# MK22F10 register map
File version: 1.6
Registers are 32-bit, read-write, reset 0x0 unless marked. A register's access mark holds for its fields unless they carry their own. Offsets are from the block's base; [hi:lo] are bit positions; {n}, {i} and the like mark numbered series; 'fields as' and 'values as' point back to an identical list.

## SIM — System Integration Module
Base 0x40047000; register names take the prefix SIM_
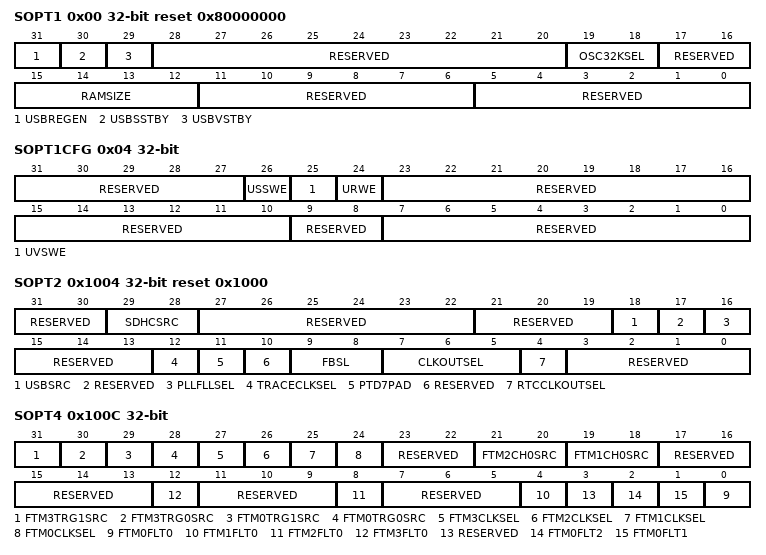
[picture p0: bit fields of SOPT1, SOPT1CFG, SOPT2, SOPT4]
0x00 SOPT1 reset 0x80000000 (reset mask 0xFFFF0FC0) — System Options Register 1
  [31] USBREGEN — USB voltage regulator enable
    0=USB voltage regulator is disabled; 1=USB voltage regulator is enabled
  [30] USBSSTBY — USB voltage regulator in standby mode during Stop, VLPS, LLS and VLLS modes.
    0=USB voltage regulator not in standby during Stop, VLPS, LLS and VLLS modes; 1=USB voltage regulator in standby during Stop, VLPS, LLS and VLLS modes
  [29] USBVSTBY — USB voltage regulator in standby mode during VLPR and VLPW modes
    0=USB voltage regulator not in standby during VLPR and VLPW modes; 1=USB voltage regulator in standby during VLPR and VLPW modes
  [28:20] RESERVED ro
  [19:18] OSC32KSEL — 32K oscillator clock select
    0=System oscillator (OSC32KCLK); 2=RTC 32.768kHz oscillator; 3=LPO 1 kHz
  [17:16] RESERVED ro
  [15:12] RAMSIZE ro
    0=Undefined; 2=Undefined; {v}=Undefined (v=4..8); 9=128 KBytes; {v}=Undefined (v=10..15)
  [11:6] RESERVED ro
  [5:0] RESERVED ro
0x04 SOPT1CFG — SOPT1 Configuration Register
  [31:27] RESERVED ro
  [26] USSWE — USB voltage regulator stop standby write enable
    0=SOPT1 USBSSTBY cannot be written; 1=SOPT1 USBSSTBY can be written
  [25] UVSWE — USB voltage regulator VLP standby write enable
    0=SOPT1 USBVSTBY cannot be written; 1=SOPT1 USBVSTBY can be written
  [24] URWE — USB voltage regulator enable write enable
    0=SOPT1 USBREGEN cannot be written; 1=SOPT1 USBREGEN can be written
  [23:10] RESERVED ro
  [9:8] RESERVED ro
  [7:0] RESERVED ro
0x1004 SOPT2 reset 0x1000 — System Options Register 2
  [31:30] RESERVED ro
  [29:28] SDHCSRC — SDHC clock source select
    0=Core/system clock; 1=MCGPLLCLK/MCGFLLCLK clock; 2=OSCERCLK clock; 3=External bypass clock (SDHC0_CLKIN)
  [27:22] RESERVED ro
  [21:19] RESERVED ro
  [18] USBSRC — USB clock source select
    0=External bypass clock (USB_CLKIN); 1=MCGPLLCLK/MCGFLLCLK clock divided by the USB fractional divider. See the SIM_CLKDIV2[USBFRAC, USBDIV] descriptions.
  [17] RESERVED ro
  [16] PLLFLLSEL — PLL/FLL clock select
    0=MCGFLLCLK clock; 1=MCGPLLCLK clock
  [15:13] RESERVED ro
  [12] TRACECLKSEL — Debug trace clock select
    0=MCGOUTCLK; 1=Core/system clock
  [11] PTD7PAD — PTD7 pad drive strength
    0=Single-pad drive strength for PTD7; 1=Double pad drive strength for PTD7
  [10] RESERVED ro
  [9:8] FBSL — FlexBus security level
    0=All off-chip accesses (instruction and data) via the FlexBus are disallowed; 1=All off-chip accesses (instruction and data) via the FlexBus are disallowed; 2=Off-chip instruction accesses are disallowed. Data accesses are allowed.; 3=Off-chip instruction accesses and data accesses are allowed
  [7:5] CLKOUTSEL — CLKOUT select
    0=FlexBus CLKOUT; 2=Flash clock; 3=LPO clock (1 kHz); 4=MCGIRCLK; 5=RTC 32.768kHz clock; 6=OSCERCLK0
  [4] RTCCLKOUTSEL — RTC clock out select
    0=RTC 1 Hz clock is output on the RTC_CLKOUT pin; 1=RTC 32.768kHz clock is output on the RTC_CLKOUT pin
  [3:0] RESERVED ro
0x100C SOPT4 — System Options Register 4
  [31] FTM3TRG1SRC — FlexTimer 3 Hardware Trigger 1 Source Select
    1=FTM2 channel match drives FTM3 hardware trigger 1
  [30] FTM3TRG0SRC — FlexTimer 3 Hardware Trigger 0 Source Select
    1=FTM1 channel match drives FTM3 hardware trigger 0
  [29] FTM0TRG1SRC — FlexTimer 0 Hardware Trigger 1 Source Select
    0=PDB output trigger 1 drives FTM0 hardware trigger 1; 1=FTM2 channel match drives FTM0 hardware trigger 1
  [28] FTM0TRG0SRC — FlexTimer 0 Hardware Trigger 0 Source Select
    0=HSCMP0 output drives FTM0 hardware trigger 0; 1=FTM1 channel match drives FTM0 hardware trigger 0
  [27] FTM3CLKSEL — FlexTimer 3 External Clock Pin Select
    0=FTM3 external clock driven by FTM_CLK0 pin; 1=FTM3 external clock driven by FTM_CLK1 pin
  [26] FTM2CLKSEL — FlexTimer 2 External Clock Pin Select
    0=FTM2 external clock driven by FTM_CLK0 pin; 1=FTM2 external clock driven by FTM_CLK1 pin
  [25] FTM1CLKSEL — FTM1 External Clock Pin Select
    0=FTM_CLK0 pin; 1=FTM_CLK1 pin
  [24] FTM0CLKSEL — FlexTimer 0 External Clock Pin Select
    0=FTM_CLK0 pin; 1=FTM_CLK1 pin
  [23:22] RESERVED ro
  [21:20] FTM2CH0SRC — FTM2 channel 0 input capture source select
    0=FTM2_CH0 signal; 1=CMP0 output; 2=CMP1 output
  [19:18] FTM1CH0SRC — FTM1 channel 0 input capture source select
    0=FTM1_CH0 signal; 1=CMP0 output; 2=CMP1 output; 3=USB start of frame pulse
  [17:13] RESERVED ro
  [4n] FTM{n}FLT0 (n=0..3) — FTM{n} Fault 0 Select
    0=FTM{n}_FLT0 pin; 1=CMP0 out
  [11:9] RESERVED ro
  [7:5] RESERVED ro
  [3] RESERVED ro
  [2] FTM0FLT2 — FTM0 Fault 2 Select
    0=FTM0_FLT2 pin; 1=CMP2 out
  [1] FTM0FLT1 — FTM0 Fault 1 Select
    0=FTM0_FLT1 pin; 1=CMP1 out
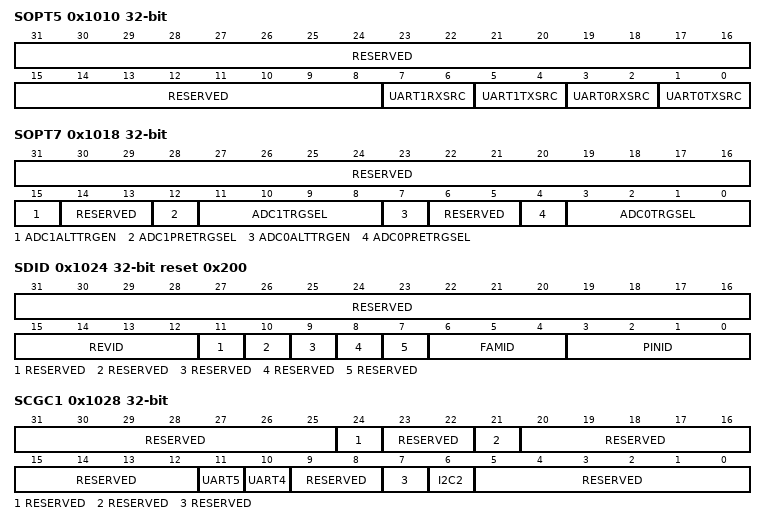
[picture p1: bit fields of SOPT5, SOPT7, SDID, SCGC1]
0x1010 SOPT5 — System Options Register 5
  [31:8] RESERVED ro
  [7:6] UART1RXSRC — UART 1 receive data source select
    0=UART1_RX pin; 1=CMP0; 2=CMP1
  [5:4] UART1TXSRC — UART 1 transmit data source select
    0=UART1_TX pin; 1=UART1_TX pin modulated with FTM1 channel 0 output; 2=UART1_TX pin modulated with FTM2 channel 0 output
  [3:2] UART0RXSRC — UART 0 receive data source select
    0=UART0_RX pin; 1=CMP0; 2=CMP1
  [1:0] UART0TXSRC — UART 0 transmit data source select
    0=UART0_TX pin; 1=UART0_TX pin modulated with FTM1 channel 0 output; 2=UART0_TX pin modulated with FTM2 channel 0 output
0x1018 SOPT7 — System Options Register 7
  [31:16] RESERVED ro
  [15] ADC1ALTTRGEN — ADC1 alternate trigger enable
    0=PDB trigger selected for ADC1; 1=Alternate trigger selected for ADC1 as defined by ADC1TRGSEL
  [14:13] RESERVED ro
  [12] ADC1PRETRGSEL — ADC1 pre-trigger select
    0=Pre-trigger A selected for ADC1; 1=Pre-trigger B selected for ADC1
  [11:8] ADC1TRGSEL — ADC1 trigger select
    0=PDB external trigger pin input (PDB0_EXTRG); 1=High speed comparator 0 output; 2=High speed comparator 1 output; 3=High speed comparator 2 output; {v}=PIT trigger {v-4} (v=4..7); 8=FTM0 trigger; 9=FTM1 trigger; 10=FTM2 trigger; 12=RTC alarm; 13=RTC seconds; 14=Low-power timer trigger
  [7] ADC0ALTTRGEN — ADC0 alternate trigger enable
    0=PDB trigger selected for ADC0; 1=Alternate trigger selected for ADC0
  [6:5] RESERVED ro
  [4] ADC0PRETRGSEL — ADC0 pretrigger select
    0=Pre-trigger A; 1=Pre-trigger B
  [3:0] ADC0TRGSEL — ADC0 trigger select
    values as ADC1TRGSEL
0x1024 SDID ro reset 0x200 (reset mask 0xF380) — System Device Identification Register
  [31:16] RESERVED
  [15:12] REVID — Device revision number
  [11] RESERVED
  [10] RESERVED
  [9] RESERVED
  [8] RESERVED
  [7] RESERVED
  [6:4] FAMID — Kinetis family identification
    1=K22
  [3:0] PINID — Pincount identification
    5=64-pin; 6=80-pin; 7=121-pin; 8=100-pin; 9=121-pin; 10=144-pin
0x1028 SCGC1 — System Clock Gating Control Register 1
  [31:25] RESERVED ro
  [24] RESERVED ro
  [23:22] RESERVED ro
  [21] RESERVED ro
  [20:12] RESERVED ro
  [11] UART5 — UART5 Clock Gate Control
    0=Clock disabled; 1=Clock enabled
  [10] UART4 — UART4 Clock Gate Control
    0=Clock disabled; 1=Clock enabled
  [9:8] RESERVED ro
  [7] RESERVED ro
  [6] I2C2 — I2C2 Clock Gate Control
    0=Clock disabled; 1=Clock enabled
  [5:0] RESERVED ro
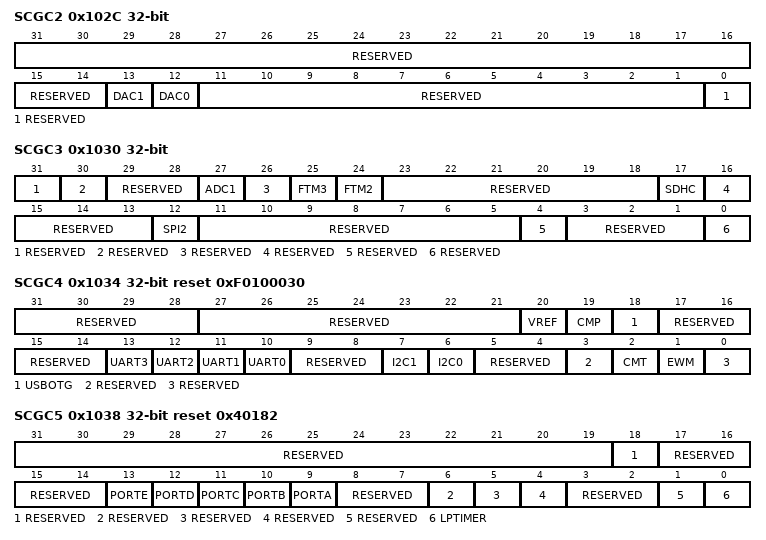
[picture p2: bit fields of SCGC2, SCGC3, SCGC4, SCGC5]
0x102C SCGC2 — System Clock Gating Control Register 2
  [31:14] RESERVED ro
  [13] DAC1 — DAC1 Clock Gate Control
    0=Clock disabled; 1=Clock enabled
  [12] DAC0 — DAC0 Clock Gate Control
    0=Clock disabled; 1=Clock enabled
  [11:1] RESERVED ro
  [0] RESERVED ro
0x1030 SCGC3 — System Clock Gating Control Register 3
  [31] RESERVED ro
  [30] RESERVED ro
  [29:28] RESERVED ro
  [27] ADC1 — ADC1 Clock Gate Control
    0=Clock disabled; 1=Clock enabled
  [26] RESERVED ro
  [25] FTM3 — FTM3 Clock Gate Control
    0=Clock disabled; 1=Clock enabled
  [24] FTM2 — FTM2 Clock Gate Control
    0=Clock disabled; 1=Clock enabled
  [23:18] RESERVED ro
  [17] SDHC — SDHC Clock Gate Control
    0=Clock disabled; 1=Clock enabled
  [16:13] RESERVED ro
  [12] SPI2 — SPI2 Clock Gate Control
    0=Clock disabled; 1=Clock enabled
  [11:5] RESERVED ro
  [4] RESERVED ro
  [3:1] RESERVED ro
  [0] RESERVED ro
0x1034 SCGC4 reset 0xF0100030 — System Clock Gating Control Register 4
  [31:28] RESERVED ro
  [27:21] RESERVED ro
  [20] VREF — VREF Clock Gate Control
    0=Clock disabled; 1=Clock enabled
  [19] CMP — Comparator Clock Gate Control
    0=Clock disabled; 1=Clock enabled
  [18] USBOTG — USB Clock Gate Control
    0=Clock disabled; 1=Clock enabled
  [17:14] RESERVED ro
  [n+10] UART{n} (n=0..3) — UART{n} Clock Gate Control
    0=Clock disabled; 1=Clock enabled
  [9:8] RESERVED ro
  [7] I2C1 — I2C1 Clock Gate Control
    0=Clock disabled; 1=Clock enabled
  [6] I2C0 — I2C0 Clock Gate Control
    0=Clock disabled; 1=Clock enabled
  [5:4] RESERVED ro
  [3] RESERVED ro
  [2] CMT — CMT Clock Gate Control
    0=Clock disabled; 1=Clock enabled
  [1] EWM — EWM Clock Gate Control
    0=Clock disabled; 1=Clock enabled
  [0] RESERVED ro
0x1038 SCGC5 reset 0x40182 — System Clock Gating Control Register 5
  [31:19] RESERVED ro
  [18] RESERVED ro
  [17:14] RESERVED ro
  [13] PORTE — Port E Clock Gate Control
    0=Clock disabled; 1=Clock enabled
  [12] PORTD — Port D Clock Gate Control
    0=Clock disabled; 1=Clock enabled
  [11] PORTC — Port C Clock Gate Control
    0=Clock disabled; 1=Clock enabled
  [10] PORTB — Port B Clock Gate Control
    0=Clock disabled; 1=Clock enabled
  [9] PORTA — Port A Clock Gate Control
    0=Clock disabled; 1=Clock enabled
  [8:7] RESERVED ro
  [6] RESERVED ro
  [5] RESERVED ro
  [4] RESERVED ro
  [3:2] RESERVED ro
  [1] RESERVED ro
  [0] LPTIMER — Low Power Timer Access Control
    0=Access disabled; 1=Access enabled
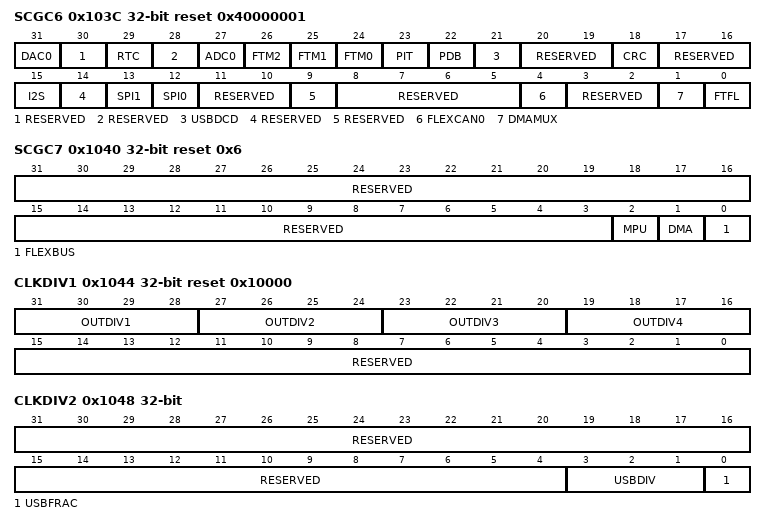
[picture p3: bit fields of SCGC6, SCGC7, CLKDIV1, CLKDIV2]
0x103C SCGC6 reset 0x40000001 — System Clock Gating Control Register 6
  [31] DAC0 — DAC0 Clock Gate Control
    0=Clock disabled; 1=Clock enabled
  [30] RESERVED ro
  [29] RTC — RTC Access Control
    0=Access and interrupts disabled; 1=Access and interrupts enabled
  [28] RESERVED ro
  [27] ADC0 — ADC0 Clock Gate Control
    0=Clock disabled; 1=Clock enabled
  [26] FTM2 — FTM2 Clock Gate Control
    0=Clock disabled; 1=Clock enabled
  [25] FTM1 — FTM1 Clock Gate Control
    0=Clock disabled; 1=Clock enabled
  [24] FTM0 — FTM0 Clock Gate Control
    0=Clock disabled; 1=Clock enabled
  [23] PIT — PIT Clock Gate Control
    0=Clock disabled; 1=Clock enabled
  [22] PDB — PDB Clock Gate Control
    0=Clock disabled; 1=Clock enabled
  [21] USBDCD — USB DCD Clock Gate Control
    0=Clock disabled; 1=Clock enabled
  [20:19] RESERVED ro
  [18] CRC — CRC Clock Gate Control
    0=Clock disabled; 1=Clock enabled
  [17:16] RESERVED ro
  [15] I2S — I2S Clock Gate Control
    0=Clock disabled; 1=Clock enabled
  [14] RESERVED ro
  [13] SPI1 — SPI1 Clock Gate Control
    0=Clock disabled; 1=Clock enabled
  [12] SPI0 — SPI0 Clock Gate Control
    0=Clock disabled; 1=Clock enabled
  [11:10] RESERVED ro
  [9] RESERVED ro
  [8:5] RESERVED ro
  [4] FLEXCAN0 — FlexCAN0 Clock Gate Control
    0=Clock disabled; 1=Clock enabled
  [3:2] RESERVED ro
  [1] DMAMUX — DMA Mux Clock Gate Control
    0=Clock disabled; 1=Clock enabled
  [0] FTFL — Flash Memory Clock Gate Control
    0=Clock disabled; 1=Clock enabled
0x1040 SCGC7 reset 0x6 — System Clock Gating Control Register 7
  [31:3] RESERVED ro
  [2] MPU — MPU Clock Gate Control
    0=Clock disabled; 1=Clock enabled
  [1] DMA — DMA Clock Gate Control
    0=Clock disabled; 1=Clock enabled
  [0] FLEXBUS — FlexBus Clock Gate Control
    0=Clock disabled; 1=Clock enabled
0x1044 CLKDIV1 reset 0x10000 — System Clock Divider Register 1
  [35-4n:32-4n] OUTDIV{n} (n=1..4) — Clock {n} output divider value
    {v}=Divide-by-{v+1} (v=0..15)
  [15:0] RESERVED ro
0x1048 CLKDIV2 — System Clock Divider Register 2
  [31:4] RESERVED ro
  [3:1] USBDIV — USB clock divider divisor
  [0] USBFRAC — USB clock divider fraction
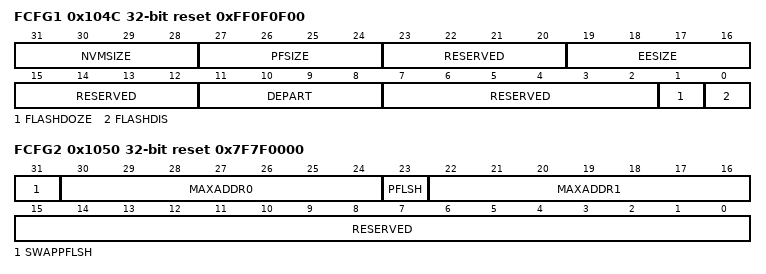
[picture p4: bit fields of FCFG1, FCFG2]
0x104C FCFG1 reset 0xFF0F0F00 — Flash Configuration Register 1
  [31:28] NVMSIZE ro — FlexNVM size
    0=0 KB of FlexNVM; 11=512 KB of FlexNVM, 64 KB protection region
  [27:24] PFSIZE ro — Program flash size
    11=512 KB of program flash, 16 KB protection region; 13=1024 KB of program flash, 32 KB protection region
  [23:20] RESERVED ro
  [19:16] EESIZE ro — EEPROM size
    2=4 KB; 3=2 KB; 4=1 KB; 5=512 Bytes; 6=256 Bytes; 7=128 Bytes; 8=64 Bytes; 9=32 Bytes; 15=0 Bytes
  [15:12] RESERVED ro
  [11:8] DEPART ro — FlexNVM partition
  [7:2] RESERVED ro
  [1] FLASHDOZE
    0=Flash remains enabled during Wait mode; 1=Flash is disabled for the duration of Wait mode
  [0] FLASHDIS — Flash Disable
    0=Flash is enabled; 1=Flash is disabled
0x1050 FCFG2 ro reset 0x7F7F0000 — Flash Configuration Register 2
  [31] SWAPPFLSH — Swap program flash
    0=Swap is not active; 1=Swap is active
  [30:24] MAXADDR0 — Max address block 0
  [23] PFLSH — Program flash
    0=Physical flash block 1 is used as FlexNVM Reserved for devices without FlexNVM; 1=Physical flash block 1 is used as program flash
  [22:16] MAXADDR1 — Max address block 1
  [15:0] RESERVED
0x1054 UIDH ro — Unique Identification Register High
  [31:0] UID — Unique Identification
0x1058 UIDMH ro — Unique Identification Register Mid-High
  [31:0] UID — Unique Identification
0x105C UIDML ro — Unique Identification Register Mid Low
  [31:0] UID — Unique Identification
0x1060 UIDL ro — Unique Identification Register Low
  [31:0] UID — Unique Identification
